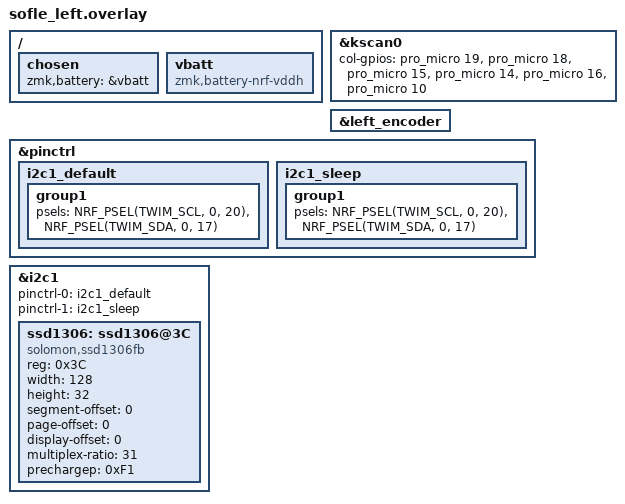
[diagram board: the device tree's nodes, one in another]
/*
 * Copyright (c) 2020 Ryan Cross
 *
 * SPDX-License-Identifier: MIT
 */

#include "sofle.dtsi"

&kscan0 {
    col-gpios = <&pro_micro 19 GPIO_ACTIVE_HIGH>,
                <&pro_micro 18 GPIO_ACTIVE_HIGH>,
                <&pro_micro 15 GPIO_ACTIVE_HIGH>,
                <&pro_micro 14 GPIO_ACTIVE_HIGH>,
                <&pro_micro 16 GPIO_ACTIVE_HIGH>,
                <&pro_micro 10 GPIO_ACTIVE_HIGH>;
};

&left_encoder {
    status = "okay";
};

&pinctrl {
    i2c1_default: i2c1_default {
        group1 {
            psels = <NRF_PSEL(TWIM_SCL, 0, 20)>, <NRF_PSEL(TWIM_SDA, 0, 17)>;
        };
    };

    i2c1_sleep: i2c1_sleep {
        group1 {
            psels = <NRF_PSEL(TWIM_SCL, 0, 20)>, <NRF_PSEL(TWIM_SDA, 0, 17)>;
        };
    };
};

&i2c1 {
    status = "okay";
    pinctrl-0 = <&i2c1_default>;
    pinctrl-1 = <&i2c1_sleep>;
    pinctrl-names = "default", "sleep";

    ssd1306: ssd1306@3C {
        compatible = "solomon,ssd1306fb";
        reg = <0x3C>;
        width = <128>;
        height = <32>;
        segment-offset = <0>;
        page-offset = <0>;
        display-offset = <0>;
        multiplex-ratio = <31>;
        prechargep = <0xF1>;
    };
};

/ {
    chosen {
        zmk,battery = &vbatt;
    };

    vbatt: vbatt {
        compatible = "zmk,battery-nrf-vddh";
    };
};
